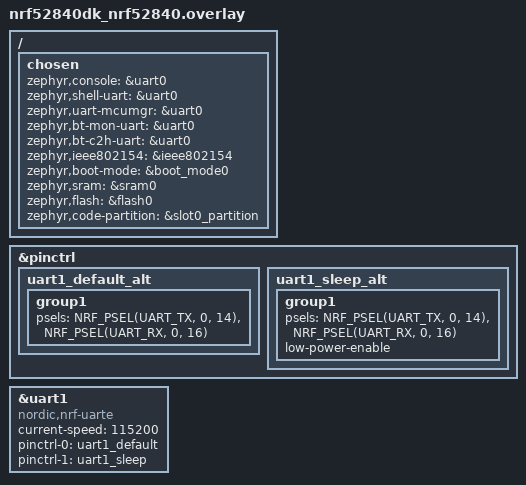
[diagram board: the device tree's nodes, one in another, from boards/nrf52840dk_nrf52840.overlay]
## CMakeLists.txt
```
cmake_minimum_required(VERSION 3.20.0)

set(CMAKE_EXPORT_COMPILE_COMMANDS ON)
find_package(Zephyr REQUIRED HINTS $ENV{ZEPHYR_BASE})
project(sample_with_mcuboot)

test_sysbuild()
zephyr_link_libraries(MCUBOOT_BOOTUTIL)

target_sources(app PRIVATE src/main.c)
```

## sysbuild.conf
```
# Sysbuild configuration file.
# See: https://docs.nordicsemi.com/bundle/ncs-latest/page/nrf/app_dev/bootloaders_dfu/mcuboot_nsib/bootloader_main_config.html

# Enable MCUboot using overwrite only mode for this sample.
SB_CONFIG_BOOTLOADER_MCUBOOT=y
SB_CONFIG_MCUBOOT_MODE_OVERWRITE_ONLY=n
SB_CONFIG_MCUBOOT_MODE_SINGLE_APP=n
# SB_CONFIG_MCUBOOT_UPDATEABLE_IMAGES=2

SB_CONFIG_BOOTLOADER_NONE=n 
#SB_CONFIG_MCUBOOT_MODE_SWAP_USING_OFFSET=y
SB_CONFIG_MCUBOOT_MODE_SWAP_USING_MOVE=y

SB_CONFIG_BOOT_SIGNATURE_TYPE_NONE=y

SB_CONFIG_BOOT_SIGNATURE_TYPE_ECDSA_P256=n
SB_CONFIG_BOOT_SIGNATURE_TYPE_RSA=n
SB_CONFIG_MCUBOOT_MODE_FIRMWARE_UPDATER=n

#SB_CONFIG_USE_DT_CODE_PARTITION=n

SB_CONFIG_WARN_EXPERIMENTAL=y
SB_CONFIG_WARN_DEPRECATED=y
```

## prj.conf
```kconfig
# MCUBoot Kconfig.mcuboot 
CONFIG_BOOTLOADER_MCUBOOT=y
CONFIG_MCUBOOT_GENERATE_UNSIGNED_IMAGE=y
CONFIG_MCUBOOT_GENERATE_CONFIRMED_IMAGE=y

# Flash
CONFIG_FLASH=y
CONFIG_STREAM_FLASH=y
CONFIG_STREAM_FLASH_PROGRESS=y
CONFIG_FLASH_MAP=y
CONFIG_STREAM_FLASH_INSPECT=y
CONFIG_STREAM_FLASH_ERASE=y

# DFU Kconfig
CONFIG_IMG_MANAGER=y
CONFIG_MCUBOOT_IMG_MANAGER=y
#CONFIG_MCUBOOT_UTIL=y
CONFIG_MCUBOOT_SHELL=y
CONFIG_UPDATEABLE_IMAGE_NUMBER=1
CONFIG_MCUBOOT_BOOTUTIL_LIB=y

CONFIG_HWINFO=y
CONFIG_STDOUT_CONSOLE=y
CONFIG_SETTINGS=y
CONFIG_SETTINGS_NONE=n
CONFIG_SETTINGS_RUNTIME=y
CONFIG_RESET=y
CONFIG_CONSOLE=y
CONFIG_REBOOT=y

CONFIG_SHELL=y
CONFIG_SHELL_MINIMAL=n 
CONFIG_SETTINGS_SHELL=y
CONFIG_KERNEL_SHELL=y
CONFIG_POSIX_ENV_SHELL=y
CONFIG_POSIX_UNAME_SHELL=y
CONFIG_UART_SHELL=y 
CONFIG_HWINFO_SHELL=y
CONFIG_FLASH_SHELL=y
CONFIG_FLASH_SHELL_TEST_COMMANDS=y
CONFIG_DEVICE_SHELL=y
CONFIG_DATE_SHELL=y
CONFIG_DEVMEM_SHELL=y
CONFIG_APP_VERSION_SHELL=y
CONFIG_SHELL_DEVICE_HELPERS=y
CONFIG_KERNEL_SHELL_PANIC_CMD=y
CONFIG_UUID=y

CONFIG_UART_CONSOLE=y
CONFIG_PRINTK=y
CONFIG_LOG_PRINTK=y
CONFIG_LOG=y

CONFIG_SIZE_OPTIMIZATIONS_AGGRESSIVE=y
CONFIG_LEGACY_GENERATED_INCLUDE_PATH=y
CONFIG_DEBUG=y
CONFIG_ASSERT_VERBOSE=y
CONFIG_COMPILER_SAVE_TEMPS=y
CONFIG_OUTPUT_PRINT_MEMORY_USAGE=y
CONFIG_BUILD_OUTPUT_META=y
CONFIG_OUTPUT_STAT=y
CONFIG_OUTPUT_SYMBOLS=y
CONFIG_CLEANUP_INTERMEDIATE_FILES=n
CONFIG_BUILD_OUTPUT_STRIP_PATHS=y
CONFIG_CHECK_INIT_PRIORITIES=y
CONFIG_SHELL_PROMPT_UART=" > "
```

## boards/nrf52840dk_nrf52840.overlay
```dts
/ {
	chosen {
		zephyr,console = &uart0;
		zephyr,shell-uart = &uart0;
		zephyr,uart-mcumgr = &uart0;
		zephyr,bt-mon-uart = &uart0;
		zephyr,bt-c2h-uart = &uart0;
		zephyr,ieee802154 = &ieee802154;
		zephyr,boot-mode = &boot_mode0;
		zephyr,sram = &sram0;
		zephyr,flash = &flash0;
		zephyr,code-partition = &slot0_partition;
	};
};

/delete-node/ &qspi;
/*
/delete-node/ &boot_partition;
/delete-node/ &slot0_partition;
/delete-node/ &slot1_partition;
/delete-node/ &storage_partition;

&flash0 {
	partitions {
		compatible = "fixed-partitions";
		#address-cells = <1>;
		#size-cells = <1>;

		boot_partition: partition@0 {
			label = "mcuboot";
			reg = <0x00000000 DT_SIZE_K(48)>;
		};

		slot0_partition: partition@c000 {
			label = "image-0";
			reg = <0x0000C000 DT_SIZE_K(220)>;
		};

		slot1_partition: partition@43000 {
			label = "image-1";
			reg = <0x00043000 DT_SIZE_K(220)>;
		};

		storage_partition: partition@f8000 {
			label = "storage";
			reg = <0x000f8000 DT_SIZE_K(1024 - 220*2 + 48)>;
		};
	};
};
*/

&pinctrl {
   uart1_default_alt: uart1_default_alt {
      group1 {
         psels = <NRF_PSEL(UART_TX, 0, 14)>,
                 <NRF_PSEL(UART_RX, 0, 16)>;
      };
   };
   /* required if CONFIG_PM_DEVICE=y */
   uart1_sleep_alt: uart1_sleep_alt {
      group1 {
         psels = <NRF_PSEL(UART_TX, 0, 14)>,
                 <NRF_PSEL(UART_RX, 0, 16)>;
         low-power-enable;
      };
   };
};

&uart1 {
	compatible = "nordic,nrf-uarte";
	status = "okay";
	current-speed = <115200>;
	pinctrl-0 = <&uart1_default>;
	pinctrl-1 = <&uart1_sleep>;
	pinctrl-names = "default", "sleep";
};
```

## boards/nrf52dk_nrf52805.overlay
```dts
	chosen {
		zephyr,console = &uart0;
		zephyr,shell-uart = &uart0;
		zephyr,uart-mcumgr = &uart0;
		zephyr,bt-mon-uart = &uart0;
		zephyr,bt-c2h-uart = &uart0;
		zephyr,sram = &sram0;
		zephyr,flash = &flash0;
		zephyr,code-partition = &slot0_partition;
	};


&flash0 {
    /delete-node/ partitions;
};
&flash0 {
	partitions {
		compatible = "fixed-partitions";
		#address-cells = <1>;
		#size-cells = <1>;

		boot_partition: partition@0 {
			label = "mcuboot";
			reg = <0x00000000 0xc000>;
		};

		slot0_partition: partition@c000 {
			label = "image-0";
			reg = <0x0000C000 0x10000>;
		};

		slot1_partition: partition@2c000 {
			label = "image-1";
			reg = <0x0001C000 0x10000>;
		};

		storage_partition: partition@8C000 {
			label = "storage";
			reg = <0x0002C000 0x4000>;
		};
	};
};
```

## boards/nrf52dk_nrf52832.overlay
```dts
/{
	chosen {
		zephyr,console = &uart0;
		zephyr,shell-uart = &uart0;
		zephyr,uart-mcumgr = &uart0;
		zephyr,bt-mon-uart = &uart0;
		zephyr,bt-c2h-uart = &uart0;
		zephyr,sram = &sram0;
		zephyr,flash = &flash0;
		zephyr,code-partition = &slot0_partition;
	};
};

/*
/delete-node/ &boot_partition;
/delete-node/ &slot0_partition;
/delete-node/ &slot1_partition;
/delete-node/ &storage_partition;

&flash0 {
	partitions {
		compatible = "fixed-partitions";
		#address-cells = <1>;
		#size-cells = <1>;

		boot_partition: partition@0 {
			label = "mcuboot";
			reg = <0x00000000 DT_SIZE_K(48)>;
		};

		slot0_partition: partition@c000 {
			label = "image-0";
			reg = <0x0000C000 DT_SIZE_K(220)>;
		};

		slot1_partition: partition@43000 {
			label = "image-1";
			reg = <0x00043000 DT_SIZE_K(220)>;
		};

		storage_partition: partition@f8000 {
			label = "storage";
			reg = <0x000f8000 DT_SIZE_K(512 - 220*2 + 48)>;
		};
	};
};
*/
```

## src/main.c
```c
/*
 * Copyright (c) 2022 Nordic Semiconductor
 *
 * SPDX-License-Identifier: Apache-2.0
 */

#include "zephyr/storage/flash_map.h"
#include <assert.h>
#include <bootutil/bootutil_public.h>
#include <zephyr/app_version.h>
#include <zephyr/dfu/mcuboot.h>
#include <zephyr/drivers/flash.h>
#include <zephyr/kernel.h>
#include <zephyr/linker/linker-defs.h>
#include <zephyr/shell/shell.h>
#include <zephyr/storage/flash_map.h>

static int version_cmd_handler(const struct shell *sh, size_t argc, char **argv,
                               void *data) {
  shell_print(sh, "%s\n", APP_VERSION_STRING);
  return 0;
}

SHELL_CMD_REGISTER(version, NULL, "Print application version.",
                   version_cmd_handler);

int main(void) {
  printk("Address of sample %p\n", (void *)__rom_region_start);
  printk("Hello sysbuild with mcuboot! %s\n", CONFIG_BOARD);
  int slot = 0;
  //  boot_request_upgrade_multi(slot, 0);
  //  int rc = boot_set_pending(0);
  //  assert(rc == 0);
  printk("Swap Type: %d\n", mcuboot_swap_type());
  printk("VERSION: %s\n", APP_VERSION_STRING);

  while (true) {
    k_sleep(K_MSEC(1000)); // sleep for 1 second
  }
  return 0;
}
```
